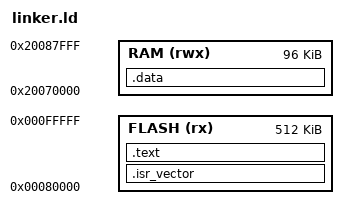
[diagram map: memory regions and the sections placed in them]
ENTRY(Reset_Handler)

MEMORY
{
  FLASH (rx)  : ORIGIN = 0x00080000, LENGTH = 512K
  RAM   (rwx) : ORIGIN = 0x20070000, LENGTH = 96K
}

_estack = ORIGIN(RAM) + LENGTH(RAM);

SECTIONS
{
  .isr_vector : { KEEP(*(.isr_vector)) } > FLASH
  .text : { *(.text*) *(.rodata*) . = ALIGN(4); _etext = .; } > FLASH
  .data : AT(_etext) { . = ALIGN(4); _sdata = .; *(.data*) . = ALIGN(4); _edata = .; } > RAM
  _sidata = LOADADDR(.data);
  .bss (NOLOAD) { . = ALIGN(4); _sbss = .; *(.bss*) *(COMMON) . = ALIGN(4); _ebss = .; } > RAM
  /DISCARD/ : { *(.comment*) *(.ARM.attributes*) }
}
